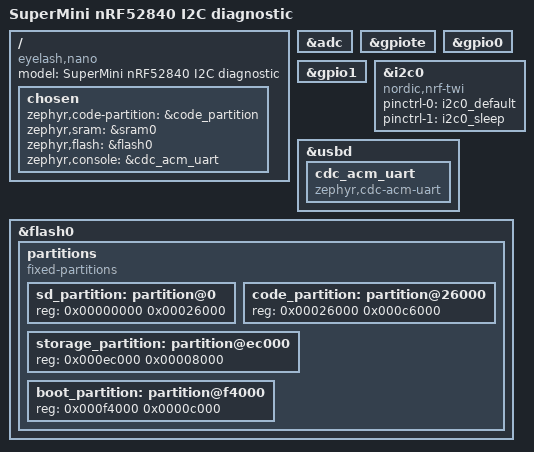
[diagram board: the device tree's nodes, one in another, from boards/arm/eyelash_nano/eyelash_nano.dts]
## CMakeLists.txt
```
cmake_minimum_required(VERSION 3.20.0)
find_package(Zephyr REQUIRED HINTS $ENV{ZEPHYR_BASE})
project(supermini_usb_diagnostic)

target_sources(app PRIVATE src/main.c)
```

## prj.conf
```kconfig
CONFIG_I2C=y
CONFIG_SERIAL=y
CONFIG_CONSOLE=y
CONFIG_UART_CONSOLE=y
CONFIG_STDOUT_CONSOLE=y
CONFIG_USB_DEVICE_STACK=y
CONFIG_USB_DEVICE_INITIALIZE_AT_BOOT=n
CONFIG_USB_CDC_ACM=y
CONFIG_UART_LINE_CTRL=y
CONFIG_PRINTK=y
CONFIG_MAIN_STACK_SIZE=2048
```

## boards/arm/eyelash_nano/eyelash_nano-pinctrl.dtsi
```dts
#include <dt-bindings/pinctrl/nrf-pinctrl.h>

&pinctrl {
    i2c0_default: i2c0_default {
        group1 {
            psels = <NRF_PSEL(TWIM_SDA, 0, 17)>,
                    <NRF_PSEL(TWIM_SCL, 0, 20)>;
        };
    };

    i2c0_sleep: i2c0_sleep {
        group1 {
            psels = <NRF_PSEL(TWIM_SDA, 0, 17)>,
                    <NRF_PSEL(TWIM_SCL, 0, 20)>;
            low-power-enable;
        };
    };
};
```

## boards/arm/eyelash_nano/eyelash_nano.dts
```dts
/dts-v1/;

#include <nordic/nrf52840_qiaa.dtsi>
#include "eyelash_nano-pinctrl.dtsi"

/ {
    model = "SuperMini nRF52840 I2C diagnostic";
    compatible = "eyelash,nano";

    chosen {
        zephyr,code-partition = &code_partition;
        zephyr,sram = &sram0;
        zephyr,flash = &flash0;
        zephyr,console = &cdc_acm_uart;
    };
};

&adc { status = "okay"; };
&gpiote { status = "okay"; };
&gpio0 { status = "okay"; };
&gpio1 { status = "okay"; };

&i2c0 {
    compatible = "nordic,nrf-twi";
    status = "okay";
    pinctrl-0 = <&i2c0_default>;
    pinctrl-1 = <&i2c0_sleep>;
    pinctrl-names = "default", "sleep";
};

&usbd {
    status = "okay";
    cdc_acm_uart: cdc_acm_uart {
        compatible = "zephyr,cdc-acm-uart";
    };
};

zephyr_udc0: &usbd { status = "okay"; };

&flash0 {
    partitions {
        compatible = "fixed-partitions";
        #address-cells = <1>;
        #size-cells = <1>;

        sd_partition: partition@0 {
            reg = <0x00000000 0x00026000>;
        };
        code_partition: partition@26000 {
            reg = <0x00026000 0x000c6000>;
        };
        storage_partition: partition@ec000 {
            reg = <0x000ec000 0x00008000>;
        };
        boot_partition: partition@f4000 {
            reg = <0x000f4000 0x0000c000>;
        };
    };
};
```

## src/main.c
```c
/*
 * Standalone SuperMini nRF52840 I2C diagnostic.
 * SPDX-License-Identifier: MIT
 */

#include <stdint.h>
#include <zephyr/device.h>
#include <zephyr/drivers/i2c.h>
#include <zephyr/drivers/uart.h>
#include <zephyr/kernel.h>
#include <zephyr/sys/printk.h>
#include <zephyr/usb/usb_device.h>

#define I2C_NODE DT_NODELABEL(i2c0)
#define CDC_NODE DT_NODELABEL(cdc_acm_uart)
#define FIRST_ADDR 0x08
#define LAST_ADDR  0x77

static const struct device *const i2c_dev = DEVICE_DT_GET(I2C_NODE);
static const struct device *const cdc_dev = DEVICE_DT_GET(CDC_NODE);

static void scan_bus(void)
{
    int found = 0;
    const uint8_t probe = 0x00;

    printk("\r\nI2C scan: SDA=P0.17 SCL=P0.20\r\n");
    for (uint16_t address = FIRST_ADDR; address <= LAST_ADDR; address++) {
        /*
         * The Nordic TWI driver is not probed with a zero-length transfer.
         * 0x00 is a valid SSD1306 command-control byte and is harmless when
         * sent without a following command byte.
         */
        int ret = i2c_write(i2c_dev, &probe, sizeof(probe), address);
        if (ret == 0) {
            printk("FOUND 0x%02x\r\n", address);
            found++;
        }
    }

    if (found == 0) {
        printk("No devices acknowledged.\r\n");
    } else {
        printk("Found %d device%s.\r\n", found, found == 1 ? "" : "s");
    }
}

int main(void)
{
    uint32_t dtr = 0U;
    int ret;

    if (!device_is_ready(cdc_dev)) {
        return 0;
    }

    /* Zephyr 3.5's CDC ACM sample enables the legacy USB stack explicitly. */
    ret = usb_enable(NULL);
    if (ret != 0) {
        return 0;
    }

    /*
     * Keep the board idle and enumerated until a serial terminal opens it.
     * No I2C access can occur before DTR is asserted by the host.
     */
    while (true) {
        ret = uart_line_ctrl_get(cdc_dev, UART_LINE_CTRL_DTR, &dtr);
        if (ret == 0 && dtr != 0U) {
            break;
        }
        k_msleep(100);
    }

    k_msleep(100);
    printk("\r\n========================================\r\n");
    printk("SuperMini standalone I2C diagnostic\r\n");
    printk("I2C0: SDA=P0.17, SCL=P0.20\r\n");
    printk("========================================\r\n");

    if (!device_is_ready(i2c_dev)) {
        printk("ERROR: i2c0 is not ready.\r\n");
        return 0;
    }

    printk("USB CDC is running; i2c0 is ready.\r\n");
    while (true) {
        scan_bus();
        k_msleep(5000);
    }
}
```
